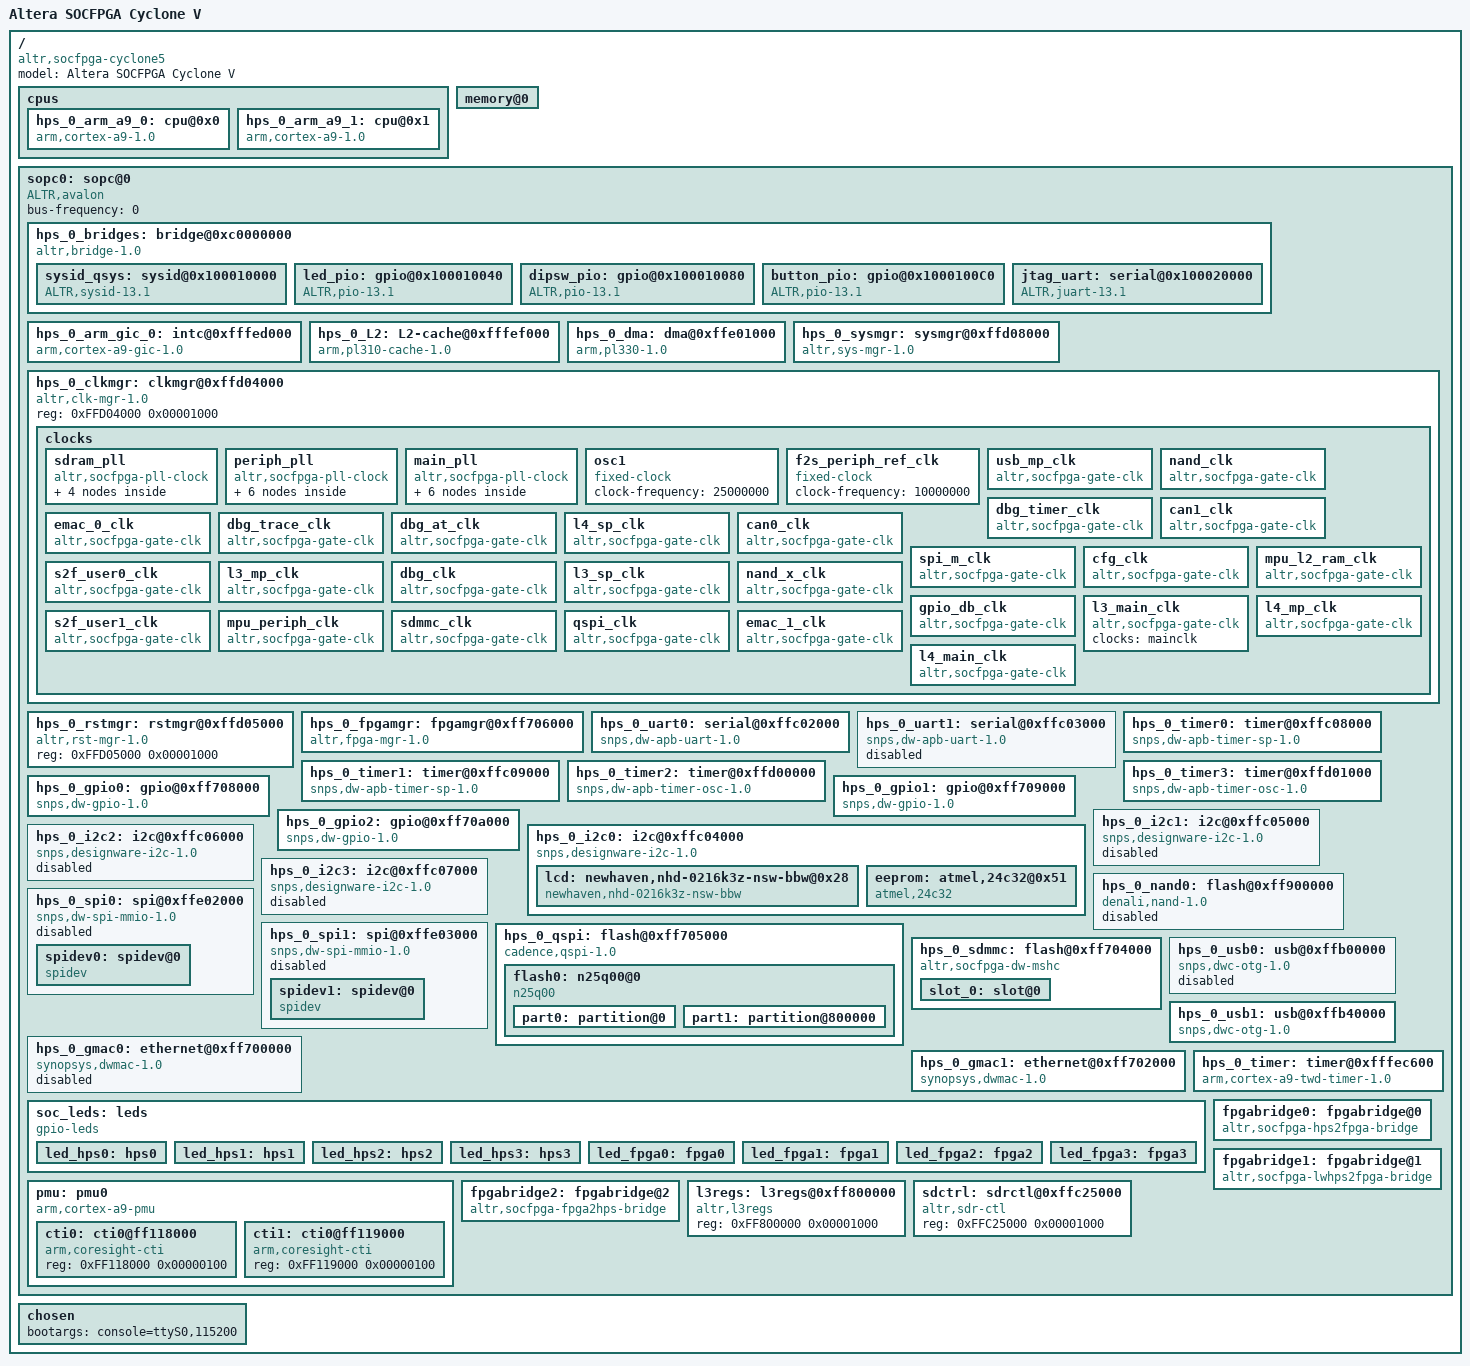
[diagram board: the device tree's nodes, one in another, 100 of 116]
/*
 * This devicetree is generated by sopc2dts on Thu Oct 24 17:41:51 PDT 2013
 * Sopc2dts is written by Walter Goossens <waltergoossens@home.nl>
 * in cooperation with the nios2 community <Nios2-dev@sopc.et.ntust.edu.tw>
 */
/dts-v1/;

/ {
	model = "Altera SOCFPGA Cyclone V";	/* appended from boardinfo */
	compatible = "altr,socfpga-cyclone5", "altr,socfpga";	/* appended from boardinfo */
	#address-cells = < 1 >;
	#size-cells = < 1 >;

	cpus {
		#address-cells = < 1 >;
		#size-cells = < 0 >;

		hps_0_arm_a9_0: cpu@0x0 {
			device_type = "cpu";
			compatible = "arm,cortex-a9-1.0", "arm,cortex-a9";
			reg = < 0x00000000 >;
			next-level-cache = < &hps_0_L2 >;	/* appended from boardinfo */
		}; //end cpu@0x0 (hps_0_arm_a9_0)

		hps_0_arm_a9_1: cpu@0x1 {
			device_type = "cpu";
			compatible = "arm,cortex-a9-1.0", "arm,cortex-a9";
			reg = < 0x00000001 >;
			next-level-cache = < &hps_0_L2 >;	/* appended from boardinfo */
		}; //end cpu@0x1 (hps_0_arm_a9_1)
	}; //end cpus

	memory@0 {
		device_type = "memory";
		reg = < 0xC0000000 0x00010000 
			0xFFFF0000 0x00010000 >;
	}; //end memory@0

	sopc0: sopc@0 {
		device_type = "soc";
		ranges;
		#address-cells = < 1 >;
		#size-cells = < 1 >;
		compatible = "ALTR,avalon", "simple-bus";
		bus-frequency = < 0 >;

		hps_0_bridges: bridge@0xc0000000 {
			compatible = "altr,bridge-1.0", "simple-bus";
			reg = < 0xC0000000 0x20000000 
				0xFF200000 0x00200000 >;
			reg-names = "axi_h2f", "axi_h2f_lw";
			#address-cells = < 2 >;
			#size-cells = < 1 >;
			ranges = < 0x00000000 0x00000000 0xC0000000 0x00010000 
				0x00000001 0x00010000 0xFF210000 0x00000008 
				0x00000001 0x00010040 0xFF210040 0x00000020 
				0x00000001 0x00010080 0xFF210080 0x00000010 
				0x00000001 0x000100C0 0xFF2100C0 0x00000010 
				0x00000001 0x00020000 0xFF220000 0x00000008 >;

			sysid_qsys: sysid@0x100010000 {
				compatible = "ALTR,sysid-13.1", "ALTR,sysid-1.0", "altr,sysid-1.0";
				reg = < 0x00000001 0x00010000 0x00000008 >;
				id = < 2899645200 >;	/* embeddedsw.dts.params.id type NUMBER */
				timestamp = < 1382661152 >;	/* embeddedsw.dts.params.timestamp type NUMBER */
			}; //end sysid@0x100010000 (sysid_qsys)

			led_pio: gpio@0x100010040 {
				compatible = "ALTR,pio-13.1", "ALTR,pio-1.0", "altr,pio-1.0";
				reg = < 0x00000001 0x00010040 0x00000020 >;
				width = < 4 >;	/* embeddedsw.dts.params.width type NUMBER */
				resetvalue = < 0 >;	/* embeddedsw.dts.params.resetvalue type NUMBER */
				#gpio-cells = < 2 >;
				gpio-controller;
			}; //end gpio@0x100010040 (led_pio)

			dipsw_pio: gpio@0x100010080 {
				compatible = "ALTR,pio-13.1", "ALTR,pio-1.0", "altr,pio-1.0";
				reg = < 0x00000001 0x00010080 0x00000010 >;
				interrupt-parent = < &hps_0_arm_gic_0 >;
				interrupts = < 0 40 1 >;
				width = < 4 >;	/* embeddedsw.dts.params.width type NUMBER */
				resetvalue = < 0 >;	/* embeddedsw.dts.params.resetvalue type NUMBER */
				edge_type = < 2 >;	/* embeddedsw.dts.params.edge_type type NUMBER */
				level_trigger = < 0 >;	/* embeddedsw.dts.params.level_trigger type NUMBER */
				#gpio-cells = < 2 >;
				gpio-controller;
			}; //end gpio@0x100010080 (dipsw_pio)

			button_pio: gpio@0x1000100C0 {
				compatible = "ALTR,pio-13.1", "ALTR,pio-1.0", "altr,pio-1.0";
				reg = < 0x00000001 0x000100C0 0x00000010 >;
				interrupt-parent = < &hps_0_arm_gic_0 >;
				interrupts = < 0 41 1 >;
				width = < 2 >;	/* embeddedsw.dts.params.width type NUMBER */
				resetvalue = < 0 >;	/* embeddedsw.dts.params.resetvalue type NUMBER */
				edge_type = < 1 >;	/* embeddedsw.dts.params.edge_type type NUMBER */
				level_trigger = < 0 >;	/* embeddedsw.dts.params.level_trigger type NUMBER */
				#gpio-cells = < 2 >;
				gpio-controller;
			}; //end gpio@0x1000100C0 (button_pio)

			jtag_uart: serial@0x100020000 {
				compatible = "ALTR,juart-13.1", "ALTR,juart-1.0", "altr,juart-1.0";
				reg = < 0x00000001 0x00020000 0x00000008 >;
				interrupt-parent = < &hps_0_arm_gic_0 >;
				interrupts = < 0 42 4 >;
			}; //end serial@0x100020000 (jtag_uart)
		}; //end bridge@0xc0000000 (hps_0_bridges)

		hps_0_arm_gic_0: intc@0xfffed000 {
			compatible = "arm,cortex-a9-gic-1.0", "arm,cortex-a9-gic";
			reg = < 0xFFFED000 0x00001000 
				0xFFFEC100 0x00000100 >;
			reg-names = "axi_slave0", "axi_slave1";
			interrupt-controller;
			#interrupt-cells = < 3 >;
		}; //end intc@0xfffed000 (hps_0_arm_gic_0)

		hps_0_L2: L2-cache@0xfffef000 {
			compatible = "arm,pl310-cache-1.0", "arm,pl310-cache";
			reg = < 0xFFFEF000 0x00001000 >;
			interrupt-parent = < &hps_0_arm_gic_0 >;
			interrupts = < 0 38 4 >;
			cache-level = < 2 >;	/* embeddedsw.dts.params.cache-level type NUMBER */
			cache-unified;	/* appended from boardinfo */
			arm,tag-latency = < 1 1 1 >;	/* appended from boardinfo */
			arm,data-latency = < 2 1 1 >;	/* appended from boardinfo */
		}; //end L2-cache@0xfffef000 (hps_0_L2)

		hps_0_dma: dma@0xffe01000 {
			compatible = "arm,pl330-1.0", "arm,pl330", "arm,primecell";
			reg = < 0xFFE01000 0x00001000 >;
			interrupt-parent = < &hps_0_arm_gic_0 >;
			interrupts = < 0 104 4 >;
		}; //end dma@0xffe01000 (hps_0_dma)

		hps_0_sysmgr: sysmgr@0xffd08000 {
			compatible = "altr,sys-mgr-1.0", "altr,sys-mgr", "syscon";
			reg = < 0xFFD08000 0x00004000 >;
			cpu1-start-addr = < 0xFFD080C4 >;	/* appended from boardinfo */
		}; //end sysmgr@0xffd08000 (hps_0_sysmgr)

		hps_0_clkmgr: clkmgr@0xffd04000 {
			compatible = "altr,clk-mgr-1.0", "altr,clk-mgr";
			reg = < 0xFFD04000 0x00001000 >;

			clocks: clocks {
				#size-cells = < 0 >;	/* appended from boardinfo */
				#address-cells = < 1 >;	/* appended from boardinfo */

				sdram_pll: sdram_pll {
					#address-cells = < 1 >;	/* appended from boardinfo */
					#size-cells = < 0 >;	/* appended from boardinfo */
					#clock-cells = < 0 >;	/* appended from boardinfo */
					compatible = "altr,socfpga-pll-clock";	/* appended from boardinfo */
					reg = < 0x000000C0 >;	/* appended from boardinfo */
					clocks = < &osc1 >;	/* appended from boardinfo */

					ddr_dqs_clk: ddr_dqs_clk {
						#clock-cells = < 0 >;	/* appended from boardinfo */
						compatible = "altr,socfpga-perip-clk";	/* appended from boardinfo */
						clocks = < &sdram_pll >;	/* appended from boardinfo */
						reg = < 0x000000C8 >;	/* appended from boardinfo */
					}; //end ddr_dqs_clk (ddr_dqs_clk)

					ddr_2x_dqs_clk: ddr_2x_dqs_clk {
						#clock-cells = < 0 >;	/* appended from boardinfo */
						compatible = "altr,socfpga-perip-clk";	/* appended from boardinfo */
						clocks = < &sdram_pll >;	/* appended from boardinfo */
						reg = < 0x000000CC >;	/* appended from boardinfo */
					}; //end ddr_2x_dqs_clk (ddr_2x_dqs_clk)

					ddr_dq_clk: ddr_dq_clk {
						#clock-cells = < 0 >;	/* appended from boardinfo */
						compatible = "altr,socfpga-perip-clk";	/* appended from boardinfo */
						clocks = < &sdram_pll >;	/* appended from boardinfo */
						reg = < 0x000000D0 >;	/* appended from boardinfo */
					}; //end ddr_dq_clk (ddr_dq_clk)

					s2f_usr2_clk: s2f_usr2_clk {
						#clock-cells = < 0 >;	/* appended from boardinfo */
						compatible = "altr,socfpga-perip-clk";	/* appended from boardinfo */
						clocks = < &sdram_pll >;	/* appended from boardinfo */
						reg = < 0x000000D4 >;	/* appended from boardinfo */
					}; //end s2f_usr2_clk (s2f_usr2_clk)
				}; //end sdram_pll (sdram_pll)

				periph_pll: periph_pll {
					#address-cells = < 1 >;	/* appended from boardinfo */
					#size-cells = < 0 >;	/* appended from boardinfo */
					#clock-cells = < 0 >;	/* appended from boardinfo */
					compatible = "altr,socfpga-pll-clock";	/* appended from boardinfo */
					reg = < 0x00000080 >;	/* appended from boardinfo */
					clocks = < &osc1 >;	/* appended from boardinfo */

					per_nand_mmc_clk: per_nand_mmc_clk {
						#clock-cells = < 0 >;	/* appended from boardinfo */
						compatible = "altr,socfpga-perip-clk";	/* appended from boardinfo */
						clocks = < &periph_pll >;	/* appended from boardinfo */
						reg = < 0x00000094 >;	/* appended from boardinfo */
					}; //end per_nand_mmc_clk (per_nand_mmc_clk)

					per_base_clk: per_base_clk {
						#clock-cells = < 0 >;	/* appended from boardinfo */
						compatible = "altr,socfpga-perip-clk";	/* appended from boardinfo */
						clocks = < &periph_pll >;	/* appended from boardinfo */
						reg = < 0x00000098 >;	/* appended from boardinfo */
					}; //end per_base_clk (per_base_clk)

					per_qspi_clk: per_qspi_clk {
						#clock-cells = < 0 >;	/* appended from boardinfo */
						compatible = "altr,socfpga-perip-clk";	/* appended from boardinfo */
						clocks = < &periph_pll >;	/* appended from boardinfo */
						reg = < 0x00000090 >;	/* appended from boardinfo */
					}; //end per_qspi_clk (per_qspi_clk)

					s2f_usr1_clk: s2f_usr1_clk {
						#clock-cells = < 0 >;	/* appended from boardinfo */
						compatible = "altr,socfpga-perip-clk";	/* appended from boardinfo */
						clocks = < &periph_pll >;	/* appended from boardinfo */
						reg = < 0x0000009C >;	/* appended from boardinfo */
					}; //end s2f_usr1_clk (s2f_usr1_clk)

					emac0_clk: emac0_clk {
						#clock-cells = < 0 >;	/* appended from boardinfo */
						compatible = "altr,socfpga-perip-clk";	/* appended from boardinfo */
						clocks = < &periph_pll >;	/* appended from boardinfo */
						reg = < 0x00000088 >;	/* appended from boardinfo */
					}; //end emac0_clk (emac0_clk)

					emac1_clk: emac1_clk {
						#clock-cells = < 0 >;	/* appended from boardinfo */
						compatible = "altr,socfpga-perip-clk";	/* appended from boardinfo */
						clocks = < &periph_pll >;	/* appended from boardinfo */
						reg = < 0x0000008C >;	/* appended from boardinfo */
					}; //end emac1_clk (emac1_clk)
				}; //end periph_pll (periph_pll)

				main_pll: main_pll {
					#address-cells = < 1 >;	/* appended from boardinfo */
					#size-cells = < 0 >;	/* appended from boardinfo */
					#clock-cells = < 0 >;	/* appended from boardinfo */
					compatible = "altr,socfpga-pll-clock";	/* appended from boardinfo */
					reg = < 0x00000040 >;	/* appended from boardinfo */
					clocks = < &osc1 >;	/* appended from boardinfo */

					cfg_s2f_usr0_clk: cfg_s2f_usr0_clk {
						#clock-cells = < 0 >;	/* appended from boardinfo */
						compatible = "altr,socfpga-perip-clk";	/* appended from boardinfo */
						clocks = < &main_pll >;	/* appended from boardinfo */
						reg = < 0x0000005C >;	/* appended from boardinfo */
					}; //end cfg_s2f_usr0_clk (cfg_s2f_usr0_clk)

					main_qspi_clk: main_qspi_clk {
						#clock-cells = < 0 >;	/* appended from boardinfo */
						compatible = "altr,socfpga-perip-clk";	/* appended from boardinfo */
						clocks = < &main_pll >;	/* appended from boardinfo */
						reg = < 0x00000054 >;	/* appended from boardinfo */
					}; //end main_qspi_clk (main_qspi_clk)

					dbg_base_clk: dbg_base_clk {
						#clock-cells = < 0 >;	/* appended from boardinfo */
						compatible = "altr,socfpga-perip-clk";	/* appended from boardinfo */
						clocks = < &main_pll >;	/* appended from boardinfo */
						fixed-divider = < 4 >;	/* appended from boardinfo */
						reg = < 0x00000050 >;	/* appended from boardinfo */
					}; //end dbg_base_clk (dbg_base_clk)

					mpuclk: mpuclk {
						#clock-cells = < 0 >;	/* appended from boardinfo */
						compatible = "altr,socfpga-perip-clk";	/* appended from boardinfo */
						clocks = < &main_pll >;	/* appended from boardinfo */
						fixed-divider = < 2 >;	/* appended from boardinfo */
						reg = < 0x00000048 >;	/* appended from boardinfo */
					}; //end mpuclk (mpuclk)

					mainclk: mainclk {
						#clock-cells = < 0 >;	/* appended from boardinfo */
						compatible = "altr,socfpga-perip-clk";	/* appended from boardinfo */
						clocks = < &main_pll >;	/* appended from boardinfo */
						fixed-divider = < 4 >;	/* appended from boardinfo */
						reg = < 0x0000004C >;	/* appended from boardinfo */
					}; //end mainclk (mainclk)

					main_nand_sdmmc_clk: main_nand_sdmmc_clk {
						#clock-cells = < 0 >;	/* appended from boardinfo */
						compatible = "altr,socfpga-perip-clk";	/* appended from boardinfo */
						clocks = < &main_pll >;	/* appended from boardinfo */
						reg = < 0x00000058 >;	/* appended from boardinfo */
					}; //end main_nand_sdmmc_clk (main_nand_sdmmc_clk)
				}; //end main_pll (main_pll)

				osc1: osc1 {
					#clock-cells = < 0 >;	/* appended from boardinfo */
					compatible = "fixed-clock";	/* appended from boardinfo */
					clock-frequency = < 25000000 >;	/* appended from boardinfo */
				}; //end osc1 (osc1)

				f2s_periph_ref_clk: f2s_periph_ref_clk {
					#clock-cells = < 0 >;	/* appended from boardinfo */
					compatible = "fixed-clock";	/* appended from boardinfo */
					clock-frequency = < 10000000 >;	/* appended from boardinfo */
				}; //end f2s_periph_ref_clk (f2s_periph_ref_clk)

				usb_mp_clk: usb_mp_clk {
					#clock-cells = < 0 >;	/* appended from boardinfo */
					compatible = "altr,socfpga-gate-clk";	/* appended from boardinfo */
					clocks = < &per_base_clk >;	/* appended from boardinfo */
					clk-gate = < 0x000000A0 2 >;	/* appended from boardinfo */
					div-reg = < 0x000000A4 0 3 >;	/* appended from boardinfo */
				}; //end usb_mp_clk (usb_mp_clk)

				nand_clk: nand_clk {
					#clock-cells = < 0 >;	/* appended from boardinfo */
					compatible = "altr,socfpga-gate-clk";	/* appended from boardinfo */
					clocks = < &f2s_periph_ref_clk &main_nand_sdmmc_clk &per_nand_mmc_clk >;	/* appended from boardinfo */
					fixed-divider = < 4 >;	/* appended from boardinfo */
					clk-gate = < 0x000000A0 10 >;	/* appended from boardinfo */
				}; //end nand_clk (nand_clk)

				dbg_timer_clk: dbg_timer_clk {
					#clock-cells = < 0 >;	/* appended from boardinfo */
					compatible = "altr,socfpga-gate-clk";	/* appended from boardinfo */
					clocks = < &dbg_base_clk >;	/* appended from boardinfo */
					clk-gate = < 0x00000060 7 >;	/* appended from boardinfo */
				}; //end dbg_timer_clk (dbg_timer_clk)

				can1_clk: can1_clk {
					#clock-cells = < 0 >;	/* appended from boardinfo */
					compatible = "altr,socfpga-gate-clk";	/* appended from boardinfo */
					clocks = < &per_base_clk >;	/* appended from boardinfo */
					clk-gate = < 0x000000A0 5 >;	/* appended from boardinfo */
					div-reg = < 0x000000A4 9 3 >;	/* appended from boardinfo */
				}; //end can1_clk (can1_clk)

				emac_0_clk: emac_0_clk {
					#clock-cells = < 0 >;	/* appended from boardinfo */
					compatible = "altr,socfpga-gate-clk";	/* appended from boardinfo */
					clocks = < &emac0_clk >;	/* appended from boardinfo */
					clk-gate = < 0x000000A0 0 >;	/* appended from boardinfo */
				}; //end emac_0_clk (emac_0_clk)

				dbg_trace_clk: dbg_trace_clk {
					#clock-cells = < 0 >;	/* appended from boardinfo */
					compatible = "altr,socfpga-gate-clk";	/* appended from boardinfo */
					clocks = < &dbg_base_clk >;	/* appended from boardinfo */
					clk-gate = < 0x00000060 6 >;	/* appended from boardinfo */
					div-reg = < 0x0000006C 0 3 >;	/* appended from boardinfo */
				}; //end dbg_trace_clk (dbg_trace_clk)

				dbg_at_clk: dbg_at_clk {
					#clock-cells = < 0 >;	/* appended from boardinfo */
					compatible = "altr,socfpga-gate-clk";	/* appended from boardinfo */
					clocks = < &dbg_base_clk >;	/* appended from boardinfo */
					clk-gate = < 0x00000060 4 >;	/* appended from boardinfo */
					div-reg = < 0x00000068 0 2 >;	/* appended from boardinfo */
				}; //end dbg_at_clk (dbg_at_clk)

				l4_sp_clk: l4_sp_clk {
					#clock-cells = < 0 >;	/* appended from boardinfo */
					compatible = "altr,socfpga-gate-clk";	/* appended from boardinfo */
					clocks = < &mainclk &per_base_clk >;	/* appended from boardinfo */
					clk-gate = < 0x00000060 3 >;	/* appended from boardinfo */
					div-reg = < 0x00000064 7 3 >;	/* appended from boardinfo */
				}; //end l4_sp_clk (l4_sp_clk)

				can0_clk: can0_clk {
					#clock-cells = < 0 >;	/* appended from boardinfo */
					compatible = "altr,socfpga-gate-clk";	/* appended from boardinfo */
					clocks = < &per_base_clk >;	/* appended from boardinfo */
					clk-gate = < 0x000000A0 4 >;	/* appended from boardinfo */
					div-reg = < 0x000000A4 6 3 >;	/* appended from boardinfo */
				}; //end can0_clk (can0_clk)

				spi_m_clk: spi_m_clk {
					#clock-cells = < 0 >;	/* appended from boardinfo */
					compatible = "altr,socfpga-gate-clk";	/* appended from boardinfo */
					clocks = < &per_base_clk >;	/* appended from boardinfo */
					clk-gate = < 0x000000A0 3 >;	/* appended from boardinfo */
					div-reg = < 0x000000A4 3 3 >;	/* appended from boardinfo */
				}; //end spi_m_clk (spi_m_clk)

				cfg_clk: cfg_clk {
					#clock-cells = < 0 >;	/* appended from boardinfo */
					compatible = "altr,socfpga-gate-clk";	/* appended from boardinfo */
					clocks = < &cfg_s2f_usr0_clk >;	/* appended from boardinfo */
					clk-gate = < 0x00000060 8 >;	/* appended from boardinfo */
				}; //end cfg_clk (cfg_clk)

				mpu_l2_ram_clk: mpu_l2_ram_clk {
					#clock-cells = < 0 >;	/* appended from boardinfo */
					compatible = "altr,socfpga-gate-clk";	/* appended from boardinfo */
					clocks = < &mpuclk >;	/* appended from boardinfo */
					fixed-divider = < 2 >;	/* appended from boardinfo */
				}; //end mpu_l2_ram_clk (mpu_l2_ram_clk)

				s2f_user0_clk: s2f_user0_clk {
					#clock-cells = < 0 >;	/* appended from boardinfo */
					compatible = "altr,socfpga-gate-clk";	/* appended from boardinfo */
					clocks = < &cfg_s2f_usr0_clk >;	/* appended from boardinfo */
					clk-gate = < 0x00000060 9 >;	/* appended from boardinfo */
				}; //end s2f_user0_clk (s2f_user0_clk)

				l3_mp_clk: l3_mp_clk {
					#clock-cells = < 0 >;	/* appended from boardinfo */
					compatible = "altr,socfpga-gate-clk";	/* appended from boardinfo */
					clocks = < &mainclk >;	/* appended from boardinfo */
					clk-gate = < 0x00000060 1 >;	/* appended from boardinfo */
					div-reg = < 0x00000064 0 2 >;	/* appended from boardinfo */
				}; //end l3_mp_clk (l3_mp_clk)

				dbg_clk: dbg_clk {
					#clock-cells = < 0 >;	/* appended from boardinfo */
					compatible = "altr,socfpga-gate-clk";	/* appended from boardinfo */
					clocks = < &dbg_base_clk >;	/* appended from boardinfo */
					clk-gate = < 0x00000060 5 >;	/* appended from boardinfo */
					div-reg = < 0x00000068 2 2 >;	/* appended from boardinfo */
				}; //end dbg_clk (dbg_clk)

				l3_sp_clk: l3_sp_clk {
					#clock-cells = < 0 >;	/* appended from boardinfo */
					compatible = "altr,socfpga-gate-clk";	/* appended from boardinfo */
					clocks = < &mainclk >;	/* appended from boardinfo */
					div-reg = < 0x00000064 2 2 >;	/* appended from boardinfo */
				}; //end l3_sp_clk (l3_sp_clk)

				nand_x_clk: nand_x_clk {
					#clock-cells = < 0 >;	/* appended from boardinfo */
					compatible = "altr,socfpga-gate-clk";	/* appended from boardinfo */
					clocks = < &f2s_periph_ref_clk &main_nand_sdmmc_clk &per_nand_mmc_clk >;	/* appended from boardinfo */
					clk-gate = < 0x000000A0 9 >;	/* appended from boardinfo */
				}; //end nand_x_clk (nand_x_clk)

				gpio_db_clk: gpio_db_clk {
					#clock-cells = < 0 >;	/* appended from boardinfo */
					compatible = "altr,socfpga-gate-clk";	/* appended from boardinfo */
					clocks = < &per_base_clk >;	/* appended from boardinfo */
					clk-gate = < 0x000000A0 6 >;	/* appended from boardinfo */
					div-reg = < 0x000000A8 0 24 >;	/* appended from boardinfo */
				}; //end gpio_db_clk (gpio_db_clk)

				l3_main_clk: l3_main_clk {
					#clock-cells = < 0 >;	/* appended from boardinfo */
					compatible = "altr,socfpga-gate-clk";	/* appended from boardinfo */
					clocks = < &mainclk >;	/* appended from boardinfo */
				}; //end l3_main_clk (l3_main_clk)

				l4_mp_clk: l4_mp_clk {
					#clock-cells = < 0 >;	/* appended from boardinfo */
					compatible = "altr,socfpga-gate-clk";	/* appended from boardinfo */
					clocks = < &mainclk >;	/* appended from boardinfo */
					clk-gate = < 0x00000060 2 >;	/* appended from boardinfo */
					div-reg = < 0x00000064 4 3 >;	/* appended from boardinfo */
				}; //end l4_mp_clk (l4_mp_clk)

				s2f_user1_clk: s2f_user1_clk {
					#clock-cells = < 0 >;	/* appended from boardinfo */
					compatible = "altr,socfpga-gate-clk";	/* appended from boardinfo */
					clocks = < &s2f_usr1_clk >;	/* appended from boardinfo */
					clk-gate = < 0x000000A0 7 >;	/* appended from boardinfo */
				}; //end s2f_user1_clk (s2f_user1_clk)

				mpu_periph_clk: mpu_periph_clk {
					#clock-cells = < 0 >;	/* appended from boardinfo */
					compatible = "altr,socfpga-gate-clk";	/* appended from boardinfo */
					clocks = < &mpuclk >;	/* appended from boardinfo */
					fixed-divider = < 4 >;	/* appended from boardinfo */
				}; //end mpu_periph_clk (mpu_periph_clk)

				sdmmc_clk: sdmmc_clk {
					#clock-cells = < 0 >;	/* appended from boardinfo */
					compatible = "altr,socfpga-gate-clk";	/* appended from boardinfo */
					clocks = < &f2s_periph_ref_clk &main_nand_sdmmc_clk &per_nand_mmc_clk >;	/* appended from boardinfo */
					clk-gate = < 0x000000A0 8 >;	/* appended from boardinfo */
				}; //end sdmmc_clk (sdmmc_clk)

				qspi_clk: qspi_clk {
					#clock-cells = < 0 >;	/* appended from boardinfo */
					compatible = "altr,socfpga-gate-clk";	/* appended from boardinfo */
					clocks = < &f2s_periph_ref_clk &main_qspi_clk &per_qspi_clk >;	/* appended from boardinfo */
					clk-gate = < 0x000000A0 11 >;	/* appended from boardinfo */
				}; //end qspi_clk (qspi_clk)

				emac_1_clk: emac_1_clk {
					#clock-cells = < 0 >;	/* appended from boardinfo */
					compatible = "altr,socfpga-gate-clk";	/* appended from boardinfo */
					clocks = < &emac1_clk >;	/* appended from boardinfo */
					clk-gate = < 0x000000A0 1 >;	/* appended from boardinfo */
				}; //end emac_1_clk (emac_1_clk)

				l4_main_clk: l4_main_clk {
					#clock-cells = < 0 >;	/* appended from boardinfo */
					compatible = "altr,socfpga-gate-clk";	/* appended from boardinfo */
					clocks = < &mainclk >;	/* appended from boardinfo */
					clk-gate = < 0x00000060 0 >;	/* appended from boardinfo */
				}; //end l4_main_clk (l4_main_clk)
			}; //end clocks (clocks)
		}; //end clkmgr@0xffd04000 (hps_0_clkmgr)

		hps_0_rstmgr: rstmgr@0xffd05000 {
			compatible = "altr,rst-mgr-1.0", "altr,rst-mgr", "syscon";
			reg = < 0xFFD05000 0x00001000 >;
		}; //end rstmgr@0xffd05000 (hps_0_rstmgr)

		hps_0_fpgamgr: fpgamgr@0xff706000 {
			compatible = "altr,fpga-mgr-1.0", "altr,fpga-mgr";
			reg = < 0xFF706000 0x00001000 
				0xFFB90000 0x00001000 >;
			reg-names = "axi_slave0", "axi_slave1";
			interrupt-parent = < &hps_0_arm_gic_0 >;
			interrupts = < 0 175 4 >;
			transport = "mmio";	/* embeddedsw.dts.params.transport type STRING */
		}; //end fpgamgr@0xff706000 (hps_0_fpgamgr)

		hps_0_uart0: serial@0xffc02000 {
			compatible = "snps,dw-apb-uart-1.0", "snps,dw-apb-uart";
			reg = < 0xFFC02000 0x00001000 >;
			interrupt-parent = < &hps_0_arm_gic_0 >;
			interrupts = < 0 162 4 >;
			reg-io-width = < 4 >;	/* embeddedsw.dts.params.reg-io-width type NUMBER */
			reg-shift = < 2 >;	/* embeddedsw.dts.params.reg-shift type NUMBER */
			clock-frequency = < 100000000 >;	/* appended from boardinfo */
		}; //end serial@0xffc02000 (hps_0_uart0)

		hps_0_uart1: serial@0xffc03000 {
			compatible = "snps,dw-apb-uart-1.0", "snps,dw-apb-uart";
			reg = < 0xFFC03000 0x00001000 >;
			interrupt-parent = < &hps_0_arm_gic_0 >;
			interrupts = < 0 163 4 >;
			reg-io-width = < 4 >;	/* embeddedsw.dts.params.reg-io-width type NUMBER */
			reg-shift = < 2 >;	/* embeddedsw.dts.params.reg-shift type NUMBER */
			clock-frequency = < 100000000 >;	/* appended from boardinfo */
			status = "disabled";	/* appended from boardinfo */
		}; //end serial@0xffc03000 (hps_0_uart1)

		hps_0_timer0: timer@0xffc08000 {
			compatible = "snps,dw-apb-timer-sp-1.0", "snps,dw-apb-timer-sp";
			reg = < 0xFFC08000 0x00001000 >;
			interrupt-parent = < &hps_0_arm_gic_0 >;
			interrupts = < 0 167 4 >;
			clock-frequency = < 100000000 >;	/* appended from boardinfo */
		}; //end timer@0xffc08000 (hps_0_timer0)

		hps_0_timer1: timer@0xffc09000 {
			compatible = "snps,dw-apb-timer-sp-1.0", "snps,dw-apb-timer-sp";
			reg = < 0xFFC09000 0x00001000 >;
			interrupt-parent = < &hps_0_arm_gic_0 >;
			interrupts = < 0 168 4 >;
			clock-frequency = < 100000000 >;	/* appended from boardinfo */
		}; //end timer@0xffc09000 (hps_0_timer1)

		hps_0_timer2: timer@0xffd00000 {
			compatible = "snps,dw-apb-timer-osc-1.0", "snps,dw-apb-timer-osc";
			reg = < 0xFFD00000 0x00001000 >;
			interrupt-parent = < &hps_0_arm_gic_0 >;
			interrupts = < 0 169 4 >;
			clock-frequency = < 25000000 >;	/* appended from boardinfo */
		}; //end timer@0xffd00000 (hps_0_timer2)

		hps_0_timer3: timer@0xffd01000 {
			compatible = "snps,dw-apb-timer-osc-1.0", "snps,dw-apb-timer-osc";
			reg = < 0xFFD01000 0x00001000 >;
			interrupt-parent = < &hps_0_arm_gic_0 >;
			interrupts = < 0 170 4 >;
			clock-frequency = < 25000000 >;	/* appended from boardinfo */
		}; //end timer@0xffd01000 (hps_0_timer3)

		hps_0_gpio0: gpio@0xff708000 {
			compatible = "snps,dw-gpio-1.0", "snps,dw-gpio";
			reg = < 0xFF708000 0x00001000 >;
			interrupt-parent = < &hps_0_arm_gic_0 >;
			interrupts = < 0 164 4 >;
			#gpio-cells = < 2 >;
			gpio-controller;
			interrupt-controller;	/* appended from boardinfo */
			#interrupt-cells = < 2 >;	/* appended from boardinfo */
			clocks = < &per_base_clk >;	/* appended from boardinfo */
		}; //end gpio@0xff708000 (hps_0_gpio0)

		hps_0_gpio1: gpio@0xff709000 {
			compatible = "snps,dw-gpio-1.0", "snps,dw-gpio";
			reg = < 0xFF709000 0x00001000 >;
			interrupt-parent = < &hps_0_arm_gic_0 >;
			interrupts = < 0 165 4 >;
			#gpio-cells = < 2 >;
			gpio-controller;
			interrupt-controller;	/* appended from boardinfo */
			#interrupt-cells = < 2 >;	/* appended from boardinfo */
			clocks = < &per_base_clk >;	/* appended from boardinfo */
		}; //end gpio@0xff709000 (hps_0_gpio1)

		hps_0_gpio2: gpio@0xff70a000 {
			compatible = "snps,dw-gpio-1.0", "snps,dw-gpio";
			reg = < 0xFF70A000 0x00001000 >;
			interrupt-parent = < &hps_0_arm_gic_0 >;
			interrupts = < 0 166 4 >;
			#gpio-cells = < 2 >;
			gpio-controller;
			interrupt-controller;	/* appended from boardinfo */
			#interrupt-cells = < 2 >;	/* appended from boardinfo */
			clocks = < &per_base_clk >;	/* appended from boardinfo */
		}; //end gpio@0xff70a000 (hps_0_gpio2)

		hps_0_i2c0: i2c@0xffc04000 {
			compatible = "snps,designware-i2c-1.0", "snps,designware-i2c";
			reg = < 0xFFC04000 0x00001000 >;
			interrupt-parent = < &hps_0_arm_gic_0 >;
			interrupts = < 0 158 4 >;
			emptyfifo_hold_master = < 1 >;	/* embeddedsw.dts.params.emptyfifo_hold_master type NUMBER */
			#address-cells = < 1 >;
			#size-cells = < 0 >;
			speed-mode = < 0 >;	/* appended from boardinfo */
			clocks = < &per_base_clk >;	/* appended from boardinfo */

			lcd: newhaven,nhd-0216k3z-nsw-bbw@0x28 {
				compatible = "newhaven,nhd-0216k3z-nsw-bbw";
				reg = < 0x00000028 >;
				height = < 2 >;	/* appended from boardinfo */
				width = < 16 >;	/* appended from boardinfo */
				brightness = < 8 >;	/* appended from boardinfo */
			}; //end newhaven,nhd-0216k3z-nsw-bbw@0x28 (lcd)

			eeprom: atmel,24c32@0x51 {
				compatible = "atmel,24c32";
				reg = < 0x00000051 >;
				pagesize = < 32 >;	/* appended from boardinfo */
			}; //end atmel,24c32@0x51 (eeprom)
		}; //end i2c@0xffc04000 (hps_0_i2c0)

		hps_0_i2c1: i2c@0xffc05000 {
			compatible = "snps,designware-i2c-1.0", "snps,designware-i2c";
			reg = < 0xFFC05000 0x00001000 >;
			interrupt-parent = < &hps_0_arm_gic_0 >;
			interrupts = < 0 159 4 >;
			emptyfifo_hold_master = < 1 >;	/* embeddedsw.dts.params.emptyfifo_hold_master type NUMBER */
			status = "disabled";	/* appended from boardinfo */
			clocks = < &per_base_clk >;	/* appended from boardinfo */
		}; //end i2c@0xffc05000 (hps_0_i2c1)

		hps_0_i2c2: i2c@0xffc06000 {
			compatible = "snps,designware-i2c-1.0", "snps,designware-i2c";
			reg = < 0xFFC06000 0x00001000 >;
			interrupt-parent = < &hps_0_arm_gic_0 >;
			interrupts = < 0 160 4 >;
			emptyfifo_hold_master = < 1 >;	/* embeddedsw.dts.params.emptyfifo_hold_master type NUMBER */
			status = "disabled";	/* appended from boardinfo */
			clocks = < &per_base_clk >;	/* appended from boardinfo */
		}; //end i2c@0xffc06000 (hps_0_i2c2)

		hps_0_i2c3: i2c@0xffc07000 {
			compatible = "snps,designware-i2c-1.0", "snps,designware-i2c";
			reg = < 0xFFC07000 0x00001000 >;
			interrupt-parent = < &hps_0_arm_gic_0 >;
			interrupts = < 0 161 4 >;
			emptyfifo_hold_master = < 1 >;	/* embeddedsw.dts.params.emptyfifo_hold_master type NUMBER */
			status = "disabled";	/* appended from boardinfo */
			clocks = < &per_base_clk >;	/* appended from boardinfo */
		}; //end i2c@0xffc07000 (hps_0_i2c3)

		hps_0_nand0: flash@0xff900000 {
			compatible = "denali,nand-1.0", "denali,denali-nand-dt";
			reg = < 0xFF900000 0x00100000 
				0xFFB80000 0x00010000 >;
			reg-names = "nand_data", "denali_reg";	/* embeddedsw.dts.params.reg-names type STRING */
			interrupt-parent = < &hps_0_arm_gic_0 >;
			interrupts = < 0 144 4 >;
			#adress-cells = < 1 >;	/* embeddedsw.dts.params.#adress-cells type NUMBER */
			#size-cells = < 1 >;	/* embeddedsw.dts.params.#size-cells type NUMBER */
			bank-width = < 2 >;
			device-width = < 1 >;
			status = "disabled";	/* appended from boardinfo */
			clocks = < &nand_clk >;	/* appended from boardinfo */
		}; //end flash@0xff900000 (hps_0_nand0)

		hps_0_spi0: spi@0xffe02000 {
			compatible = "snps,dw-spi-mmio-1.0", "snps,dw-spi-mmio";
			reg = < 0xFFE02000 0x00001000 >;
			interrupt-parent = < &hps_0_arm_gic_0 >;
			interrupts = < 0 154 4 >;
			#address-cells = < 1 >;	/* embeddedsw.dts.params.#address-cells type NUMBER */
			#size-cells = < 0 >;	/* embeddedsw.dts.params.#size-cells type NUMBER */
			bus-num = < 0 >;	/* embeddedsw.dts.params.bus-num type NUMBER */
			num-chipselect = < 4 >;	/* embeddedsw.dts.params.num-chipselect type NUMBER */
			status = "disabled";	/* appended from boardinfo */
			clocks = < &per_base_clk >;	/* appended from boardinfo */

			spidev0: spidev@0 {
				compatible = "spidev";	/* appended from boardinfo */
				reg = < 0 >;	/* appended from boardinfo */
				spi-max-frequency = < 100000000 >;	/* appended from boardinfo */
				enable-dma = < 1 >;	/* appended from boardinfo */
			}; //end spidev@0 (spidev0)
		}; //end spi@0xffe02000 (hps_0_spi0)

		hps_0_spi1: spi@0xffe03000 {
			compatible = "snps,dw-spi-mmio-1.0", "snps,dw-spi-mmio";
			reg = < 0xFFE03000 0x00001000 >;
			interrupt-parent = < &hps_0_arm_gic_0 >;
			interrupts = < 0 155 4 >;
			#address-cells = < 1 >;	/* embeddedsw.dts.params.#address-cells type NUMBER */
			#size-cells = < 0 >;	/* embeddedsw.dts.params.#size-cells type NUMBER */
			bus-num = < 0 >;	/* embeddedsw.dts.params.bus-num type NUMBER */
			num-chipselect = < 4 >;	/* embeddedsw.dts.params.num-chipselect type NUMBER */
			status = "disabled";	/* appended from boardinfo */
			clocks = < &per_base_clk >;	/* appended from boardinfo */

			spidev1: spidev@0 {
				compatible = "spidev";	/* appended from boardinfo */
				reg = < 0 >;	/* appended from boardinfo */
				spi-max-frequency = < 100000000 >;	/* appended from boardinfo */
				enable-dma = < 1 >;	/* appended from boardinfo */
			}; //end spidev@0 (spidev1)
		}; //end spi@0xffe03000 (hps_0_spi1)

		hps_0_qspi: flash@0xff705000 {
			compatible = "cadence,qspi-1.0", "cadence,qspi";
			reg = < 0xFF705000 0x00001000 
				0xFFA00000 0x00001000 >;
			reg-names = "axi_slave0", "axi_slave1";
			interrupt-parent = < &hps_0_arm_gic_0 >;
			interrupts = < 0 151 4 >;
			bus-num = < 2 >;	/* embeddedsw.dts.params.bus-num type NUMBER */
			fifo-depth = < 128 >;	/* embeddedsw.dts.params.fifo-depth type NUMBER */
			num-chipselect = < 4 >;	/* embeddedsw.dts.params.num-chipselect type NUMBER */
			bank-width = < 2 >;
			device-width = < 1 >;
			master-ref-clk = < 400000000 >;	/* appended from boardinfo */
			ext-decoder = < 0 >;	/* appended from boardinfo */
			#address-cells = < 1 >;	/* appended from boardinfo */
			#size-cells = < 0 >;	/* appended from boardinfo */

			flash0: n25q00@0 {
				#address-cells = < 1 >;	/* appended from boardinfo */
				#size-cells = < 1 >;	/* appended from boardinfo */
				compatible = "n25q00";	/* appended from boardinfo */
				reg = < 0 >;	/* appended from boardinfo */
				spi-max-frequency = < 100000000 >;	/* appended from boardinfo */
				page-size = < 256 >;	/* appended from boardinfo */
				block-size = < 16 >;	/* appended from boardinfo */
				m25p,fast-read;	/* appended from boardinfo */
				read-delay = < 4 >;	/* appended from boardinfo */
				tshsl-ns = < 50 >;	/* appended from boardinfo */
				tsd2d-ns = < 50 >;	/* appended from boardinfo */
				tchsh-ns = < 4 >;	/* appended from boardinfo */
				tslch-ns = < 4 >;	/* appended from boardinfo */

				part0: partition@0 {
					label = "Flash 0 Raw Data";	/* appended from boardinfo */
					reg = < 0x00000000 0x00800000 >;	/* appended from boardinfo */
				}; //end partition@0 (part0)

				part1: partition@800000 {
					label = "Flash 1 jffs2 Filesystem";	/* appended from boardinfo */
					reg = < 0x00800000 0x00800000 >;	/* appended from boardinfo */
				}; //end partition@800000 (part1)
			}; //end n25q00@0 (flash0)
		}; //end flash@0xff705000 (hps_0_qspi)

		hps_0_sdmmc: flash@0xff704000 {
			compatible = "altr,socfpga-dw-mshc";	/* appended from boardinfo */
			reg = < 0xFF704000 0x00001000 >;
			interrupt-parent = < &hps_0_arm_gic_0 >;
			interrupts = < 0 139 4 >;
			fifo-depth = < 1024 >;	/* embeddedsw.dts.params.fifo-depth type NUMBER */
			num-slots = < 1 >;	/* embeddedsw.dts.params.num-slots type NUMBER */
			bank-width = < 2 >;
			device-width = < 1 >;
			clocks = < &l4_mp_clk &sdmmc_clk >;	/* appended from boardinfo */
			clock-names = "biu", "ciu";	/* appended from boardinfo */
			#address-cells = < 1 >;	/* appended from boardinfo */
			#size-cells = < 0 >;	/* appended from boardinfo */
			supports-highspeed;	/* appended from boardinfo */
			broken-cd;	/* appended from boardinfo */
			altr,dw-mshc-ciu-div = < 3 >;	/* appended from boardinfo */
			altr,dw-mshc-sdr-timing = < 0 3 >;	/* appended from boardinfo */

			slot_0: slot@0 {
				reg = < 0 >;	/* appended from boardinfo */
				bus-width = < 4 >;	/* appended from boardinfo */
			}; //end slot@0 (slot_0)
		}; //end flash@0xff704000 (hps_0_sdmmc)

		hps_0_usb0: usb@0xffb00000 {
			compatible = "snps,dwc-otg-1.0", "snps,dwc-otg";
			reg = < 0xFFB00000 0x00001000 >;
			interrupt-parent = < &hps_0_arm_gic_0 >;
			interrupts = < 0 125 4 >;
			dev-nperio-tx-fifo-size = < 4096 >;	/* embeddedsw.dts.params.dev-nperio-tx-fifo-size type NUMBER */
			dev-perio-tx-fifo-size = "<512 512 512 512 512 512 512 512 512 512 512 512 512 512 512>";	/* embeddedsw.dts.params.dev-perio-tx-fifo-size type STRING */
			dev-tx-fifo-size = "<512 512 512 512 512 512 512 512 512 512 512 512 512 512 512>";	/* embeddedsw.dts.params.dev-tx-fifo-size type STRING */
			dev_rx_fifo-size = < 512 >;	/* embeddedsw.dts.params.dev_rx_fifo-size type NUMBER */
			dma-mask = < 268435455 >;	/* embeddedsw.dts.params.dma-mask type NUMBER */
			host_rx_fifo-size = < 512 >;	/* embeddedsw.dts.params.host_rx_fifo-size type NUMBER */
			ulpi-ddr = < 0 >;	/* embeddedsw.dts.params.ulpi-ddr type NUMBER */
			voltage-switch = < 0 >;	/* embeddedsw.dts.params.voltage-switch type NUMBER */
			status = "disabled";	/* appended from boardinfo */
		}; //end usb@0xffb00000 (hps_0_usb0)

		hps_0_usb1: usb@0xffb40000 {
			compatible = "snps,dwc-otg-1.0", "snps,dwc-otg";
			reg = < 0xFFB40000 0x00001000 >;
			interrupt-parent = < &hps_0_arm_gic_0 >;
			interrupts = < 0 128 4 >;
			dev-nperio-tx-fifo-size = < 4096 >;	/* embeddedsw.dts.params.dev-nperio-tx-fifo-size type NUMBER */
			dev-perio-tx-fifo-size = "<512 512 512 512 512 512 512 512 512 512 512 512 512 512 512>";	/* embeddedsw.dts.params.dev-perio-tx-fifo-size type STRING */
			dev-tx-fifo-size = "<512 512 512 512 512 512 512 512 512 512 512 512 512 512 512>";	/* embeddedsw.dts.params.dev-tx-fifo-size type STRING */
			dev_rx_fifo-size = < 512 >;	/* embeddedsw.dts.params.dev_rx_fifo-size type NUMBER */
			dma-mask = < 268435455 >;	/* embeddedsw.dts.params.dma-mask type NUMBER */
			host_rx_fifo-size = < 512 >;	/* embeddedsw.dts.params.host_rx_fifo-size type NUMBER */
			ulpi-ddr = < 0 >;	/* embeddedsw.dts.params.ulpi-ddr type NUMBER */
			voltage-switch = < 0 >;	/* embeddedsw.dts.params.voltage-switch type NUMBER */
		}; //end usb@0xffb40000 (hps_0_usb1)

		hps_0_gmac0: ethernet@0xff700000 {
			compatible = "synopsys,dwmac-1.0", "altr,socfpga-stmmac", "snps,dwmac-3.70a", "snps,dwmac";
			reg = < 0xFF700000 0x00002000 >;
			interrupt-parent = < &hps_0_arm_gic_0 >;
			interrupts = < 0 115 4 >;
			interrupt-names = "macirq";	/* embeddedsw.dts.params.interrupt-names type STRING */
			mac-address = "[00 00 00 00 00 00]";	/* embeddedsw.dts.params.mac-address type STRING */
			address-bits = < 48 >;
			max-frame-size = < 1518 >;
			local-mac-address = [ 00 00 00 00 00 00 ];
			clock-names = "stmmaceth";	/* appended from boardinfo */
			clocks = < &emac0_clk >;	/* appended from boardinfo */
			status = "disabled";	/* appended from boardinfo */
		}; //end ethernet@0xff700000 (hps_0_gmac0)

		hps_0_gmac1: ethernet@0xff702000 {
			compatible = "synopsys,dwmac-1.0", "altr,socfpga-stmmac", "snps,dwmac-3.70a", "snps,dwmac";
			reg = < 0xFF702000 0x00002000 >;
			interrupt-parent = < &hps_0_arm_gic_0 >;
			interrupts = < 0 120 4 >;
			interrupt-names = "macirq";	/* embeddedsw.dts.params.interrupt-names type STRING */
			mac-address = "[00 00 00 00 00 00]";	/* embeddedsw.dts.params.mac-address type STRING */
			address-bits = < 48 >;
			max-frame-size = < 1518 >;
			local-mac-address = [ 00 00 00 00 00 00 ];
			phy-mode = "rgmii";	/* appended from boardinfo */
			clock-names = "stmmaceth";	/* appended from boardinfo */
			clocks = < &emac1_clk >;	/* appended from boardinfo */
			phy-addr = < 0xFFFFFFFF >;	/* appended from boardinfo */
			micrel-ksz9021rlrn-clk-skew = < 0x0000A0E0 >;	/* appended from boardinfo */
			micrel-ksz9021rlrn-rx-skew = < 0x00000000 >;	/* appended from boardinfo */
		}; //end ethernet@0xff702000 (hps_0_gmac1)

		hps_0_timer: timer@0xfffec600 {
			compatible = "arm,cortex-a9-twd-timer-1.0", "arm,cortex-a9-twd-timer";
			reg = < 0xFFFEC600 0x00000100 >;
			interrupt-parent = < &hps_0_arm_gic_0 >;
			interrupts = < 1 13 3844 >;
		}; //end timer@0xfffec600 (hps_0_timer)

		soc_leds: leds {
			compatible = "gpio-leds";	/* appended from boardinfo */

			led_hps0: hps0 {
				label = "hps_led0";	/* appended from boardinfo */
				gpios = < &hps_0_gpio1 15 1 >;	/* appended from boardinfo */
			}; //end hps0 (led_hps0)

			led_hps1: hps1 {
				label = "hps_led1";	/* appended from boardinfo */
				gpios = < &hps_0_gpio1 14 1 >;	/* appended from boardinfo */
			}; //end hps1 (led_hps1)

			led_hps2: hps2 {
				label = "hps_led2";	/* appended from boardinfo */
				gpios = < &hps_0_gpio1 13 1 >;	/* appended from boardinfo */
			}; //end hps2 (led_hps2)

			led_hps3: hps3 {
				label = "hps_led3";	/* appended from boardinfo */
				gpios = < &hps_0_gpio1 12 1 >;	/* appended from boardinfo */
			}; //end hps3 (led_hps3)

			led_fpga0: fpga0 {
				label = "fpga_led0";	/* appended from boardinfo */
				gpios = < &led_pio 0 1 >;	/* appended from boardinfo */
			}; //end fpga0 (led_fpga0)

			led_fpga1: fpga1 {
				label = "fpga_led1";	/* appended from boardinfo */
				gpios = < &led_pio 1 1 >;	/* appended from boardinfo */
			}; //end fpga1 (led_fpga1)

			led_fpga2: fpga2 {
				label = "fpga_led2";	/* appended from boardinfo */
				gpios = < &led_pio 2 1 >;	/* appended from boardinfo */
			}; //end fpga2 (led_fpga2)

			led_fpga3: fpga3 {
				label = "fpga_led3";	/* appended from boardinfo */
				gpios = < &led_pio 3 1 >;	/* appended from boardinfo */
			}; //end fpga3 (led_fpga3)
		}; //end leds (soc_leds)

		pmu: pmu0 {
			#address-cells = < 1 >;	/* appended from boardinfo */
			#size-cells = < 1 >;	/* appended from boardinfo */
			compatible = "arm,cortex-a9-pmu";	/* appended from boardinfo */
			interrupt-parent = < &hps_0_arm_gic_0 >;	/* appended from boardinfo */
			interrupts = < 0 176 4 0 177 4 >;	/* appended from boardinfo */
			ranges;	/* appended from boardinfo */

			cti0: cti0@ff118000 {
				compatible = "arm,coresight-cti";	/* appended from boardinfo */
				reg = < 0xFF118000 0x00000100 >;	/* appended from boardinfo */
			}; //end cti0@ff118000 (cti0)

			cti1: cti0@ff119000 {
				compatible = "arm,coresight-cti";	/* appended from boardinfo */
				reg = < 0xFF119000 0x00000100 >;	/* appended from boardinfo */
			}; //end cti0@ff119000 (cti1)
		}; //end pmu0 (pmu)

		fpgabridge0: fpgabridge@0 {
			compatible = "altr,socfpga-hps2fpga-bridge";	/* appended from boardinfo */
			label = "hps2fpga";	/* appended from boardinfo */
			clocks = < &l4_main_clk >;	/* appended from boardinfo */
		}; //end fpgabridge@0 (fpgabridge0)

		fpgabridge1: fpgabridge@1 {
			compatible = "altr,socfpga-lwhps2fpga-bridge";	/* appended from boardinfo */
			label = "lwhps2fpga";	/* appended from boardinfo */
			clocks = < &l4_main_clk >;	/* appended from boardinfo */
		}; //end fpgabridge@1 (fpgabridge1)

		fpgabridge2: fpgabridge@2 {
			compatible = "altr,socfpga-fpga2hps-bridge";	/* appended from boardinfo */
			label = "fpga2hps";	/* appended from boardinfo */
			clocks = < &l4_main_clk >;	/* appended from boardinfo */
		}; //end fpgabridge@2 (fpgabridge2)

		l3regs: l3regs@0xff800000 {
			compatible = "altr,l3regs", "syscon";	/* appended from boardinfo */
			reg = < 0xFF800000 0x00001000 >;	/* appended from boardinfo */
		}; //end l3regs@0xff800000 (l3regs)

		sdctrl: sdrctl@0xffc25000 {
			compatible = "altr,sdr-ctl", "syscon";	/* appended from boardinfo */
			reg = < 0xFFC25000 0x00001000 >;	/* appended from boardinfo */
		}; //end sdrctl@0xffc25000 (sdctrl)
	}; //end sopc@0 (sopc0)

	chosen {
		bootargs = "console=ttyS0,115200";
	}; //end chosen
}; //end /
